# sam67_dmpac_wrap0_DMPAC_TOP_CFG_SLV_DRU_UTC_DMPAC0_DRU_MMR_CFG_DRU_DRU_QUEUE register map
Vendor: Texas Instruments
Peripheral module from a debugger description file (folder J722S).
Registers are 64-bit, access per field, reset 0x0 unless marked. A register's access mark holds for its fields unless they carry their own. Offsets are as the file gives them; lines under a group give offsets from that group; [hi:lo] are bit positions; {n}, {i} and the like mark numbered series; 'fields as' and 'values as' point back to an identical list; <NAME> marks a mode.

## sam67_dmpac_wrap0_DMPAC_TOP_CFG_SLV_DRU_UTC_DMPAC0_DRU_MMR_CFG_DRU_DRU_QUEUE
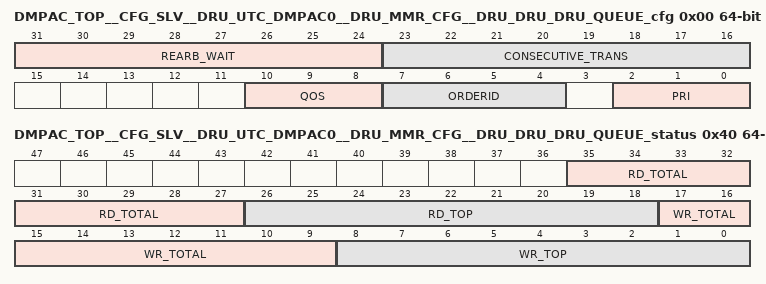
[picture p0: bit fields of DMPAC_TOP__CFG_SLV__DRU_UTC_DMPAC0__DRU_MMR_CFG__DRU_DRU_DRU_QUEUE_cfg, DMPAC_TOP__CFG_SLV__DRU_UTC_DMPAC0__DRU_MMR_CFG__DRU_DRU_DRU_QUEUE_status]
0x00 DMPAC_TOP__CFG_SLV__DRU_UTC_DMPAC0__DRU_MMR_CFG__DRU_DRU_DRU_QUEUE_cfg — Configuration Register for Queue 0
  [31:24] REARB_WAIT rw — This is the number of commands that will be sent by other queues before allowing the queue to arbitrate again for the right to send commands. This is only started when a queue exhausted its consecutive trans count.
  [23:16] CONSECUTIVE_TRANS rw — This is the number of consecutive transactions that will be sent before allowing another queue of equal level to arbitrate to send commands. This is the maximum number of commands that it can send. If the queue has any delays such as virtual address lookup then the arbitration will be forced regardless of the number of commands.
  [10:8] QOS rw — This configures the QOS for QUEUE0. This should only be set for fixed priority queues and the lower queue should have the lower QoS.
  [7:4] ORDERID rw — This configures the orderid for QUEUE0.
  [2:0] PRI rw — This configures the priority for QUEUE0. This will be the priority that will be presented on the External bus for all commands from this queue.
0x40 DMPAC_TOP__CFG_SLV__DRU_UTC_DMPAC0__DRU_MMR_CFG__DRU_DRU_DRU_QUEUE_status ro — Status Register for Queue 0
  [35:27] RD_TOTAL — This is the channel that the read half is currently working on.
  [26:18] RD_TOP — This is the channel that the read half is currently working on.
  [17:9] WR_TOTAL — This is the channel that the read half is currently working on.
  [8:0] WR_TOP — This is the channel that the write half is currently working on.
